VERSION ""

NS_ :

BS_:
BU_: DME_Etc
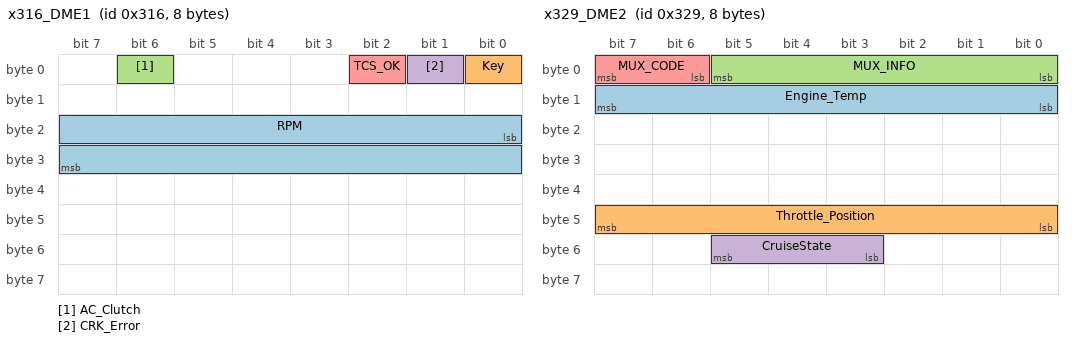
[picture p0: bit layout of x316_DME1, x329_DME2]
BO_ 790 x316_DME1: 8 DME_Etc
   SG_ RPM : 16|16@1+ (0.156,0) [0|0] "" DME_Etc
   SG_ Key : 0|1@1+ (1,0) [0|0] "" Vector__XXX
   SG_ AC_Clutch : 6|1@1+ (1,0) [0|0] "" Vector__XXX
   SG_ CRK_Error : 1|1@1+ (1,0) [0|0] "" Vector__XXX
   SG_ TCS_OK : 2|1@1+ (1,0) [0|0] "" Vector__XXX

BO_ 809 x329_DME2: 8 DME_Etc
   SG_ Engine_Temp : 8|8@1+ (0.75,-48.373) [0|0] "deg_c" Vector__XXX
   SG_ Throttle_Position : 40|8@1+ (1,0) [0|0] "%" DME_Etc
   SG_ MUX_INFO : 0|6@1+ (1,0) [0|0] "" DME_Etc
   SG_ CruiseState : 51|3@1+ (1,0) [0|0] "" DME_Etc
   SG_ MUX_CODE : 6|2@1+ (1,0) [0|0] "" DME_Etc

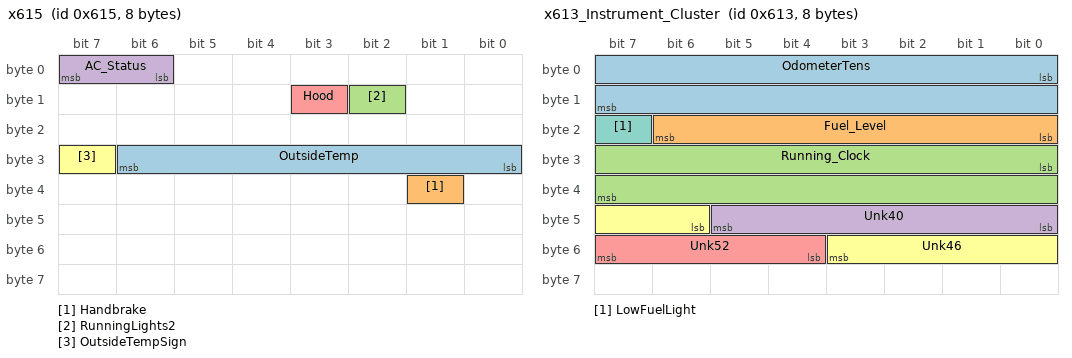
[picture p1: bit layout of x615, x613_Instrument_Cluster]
BO_ 1557 x615: 8 DME_Etc
   SG_ OutsideTemp : 24|7@1+ (1,0) [0|0] "deg_c" Vector__XXX
   SG_ Handbrake : 33|1@0+ (1,0) [0|1] "" Vector__XXX
   SG_ RunningLights2 : 10|1@0+ (1,0) [0|1] "" Vector__XXX
   SG_ AC_Status : 6|2@1+ (1,0) [0|1] "" Vector__XXX
   SG_ Hood : 11|1@0+ (1,0) [0|1] "" Vector__XXX
   SG_ OutsideTempSign : 31|1@1+ (1,0) [0|0] "" Vector__XXX

BO_ 1349 x545_DME4: 8 DME_Etc
   SG_ Fuel_Consumption : 8|16@1+ (1,0) [0|0] "mpg" DME_Etc
   SG_ Charge_Light : 40|1@1+ (1,0) [0|0] "" Vector__XXX
   SG_ Oil_Pressure_Light : 44|1@1+ (1,0) [0|0] "" DME_Etc
   SG_ OilTemp : 32|8@1+ (1,-48.373) [0|0] "deg_c" DME_Etc
   SG_ CheckEngineLight : 1|1@1+ (1,0) [0|0] "" Vector__XXX
   SG_ CruiseLight : 3|1@1+ (1,0) [0|0] "" Vector__XXX
   SG_ EML : 4|1@1+ (1,0) [0|0] "" Vector__XXX
   SG_ CheckGasCap : 6|1@1+ (1,0) [0|0] "" Vector__XXX
   SG_ OverheatLight : 27|1@1+ (1,0) [0|0] "" DME_Etc
   SG_ OilLoss : 25|1@1+ (1,0) [0|0] "" DME_Etc
   SG_ RPM7k : 28|1@1+ (1,0) [0|0] "" DME_Etc
   SG_ RPM6_5k : 29|1@1+ (1,0) [0|0] "" DME_Etc
   SG_ RPM5_5k : 30|1@1+ (1,0) [0|0] "" DME_Etc
   SG_ Unk7 : 56|8@1+ (1,0) [0|0] "" Vector__XXX
   SG_ OilConsumption : 24|1@1+ (1,0) [0|0] "" DME_Etc
   SG_ OilSensorMalfunction : 26|1@1+ (1,0) [0|0] "" DME_Etc
   SG_ UpshiftIndicator : 31|1@1+ (1,0) [0|0] "" DME_Etc

BO_ 1555 x613_Instrument_Cluster: 8 DME_Etc
   SG_ OdometerTens : 0|16@1+ (10,0) [0|0] "" Vector__XXX
   SG_ Fuel_Level : 16|7@1+ (1,0) [0|0] "" Vector__XXX
   SG_ Running_Clock : 24|16@1+ (1,0) [0|0] "minutes" DME_Etc
   SG_ Unk40 : 40|6@1+ (1,0) [0|1] "" Vector__XXX
   SG_ Unk52 : 52|4@1+ (1,0) [0|1] "" Vector__XXX
   SG_ Unk46 : 46|6@1+ (1,0) [0|1] "" Vector__XXX
   SG_ LowFuelLight : 23|1@1+ (1,0) [0|0] "" Vector__XXX

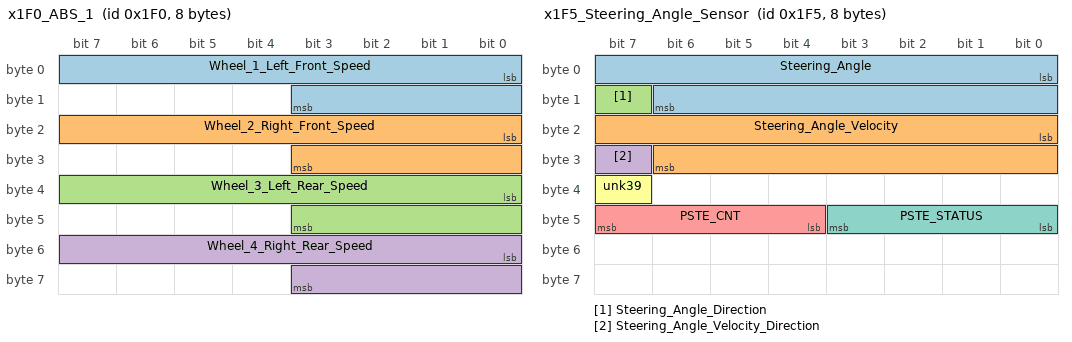
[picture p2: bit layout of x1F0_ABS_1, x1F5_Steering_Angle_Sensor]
BO_ 496 x1F0_ABS_1: 8 DME_Etc
   SG_ Wheel_1_Left_Front_Speed : 0|12@1+ (0.0625,0) [0|0] "" Vector__XXX
   SG_ Wheel_2_Right_Front_Speed : 16|12@1+ (0.0625,0) [0|0] "" DME_Etc
   SG_ Wheel_3_Left_Rear_Speed : 32|12@1+ (0.0625,0) [0|0] "" DME_Etc
   SG_ Wheel_4_Right_Rear_Speed : 48|12@1+ (0.0625,0) [0|0] "" Vector__XXX

BO_ 501 x1F5_Steering_Angle_Sensor: 8 DME_Etc
   SG_ Steering_Angle : 0|15@1+ (0.045,0) [0|0] "deg" DME_Etc
   SG_ Steering_Angle_Velocity : 16|15@1+ (0.045,0) [0|0] "deg_per_sec" DME_Etc
   SG_ Steering_Angle_Direction : 15|1@1+ (1,0) [0|0] "" Vector__XXX
   SG_ Steering_Angle_Velocity_Direction : 31|1@1+ (1,0) [0|0] "" Vector__XXX
   SG_ PSTE_CNT : 44|4@1+ (1,0) [0|0] "" Vector__XXX
   SG_ unk39 : 39|1@1+ (1,0) [0|0] "" Vector__XXX
   SG_ PSTE_STATUS : 40|4@1+ (1,0) [0|0] "" Vector__XXX

BO_ 339 ASC_1: 8 DME_Etc
   SG_ Speed : 11|13@1+ (0.0625,-0.625) [0|0] "" DME_Etc
   SG_ Brake_Pedal_Pressed : 4|1@1+ (1,0) [0|0] "" Vector__XXX
   SG_ Tyre_Pressure_Set : 0|1@1+ (1,0) [0|0] "" Vector__XXX
   SG_ Unk5 : 40|8@1+ (1,0) [0|0] "" Vector__XXX
   SG_ CheckEngineLight : 9|1@1+ (1,0) [0|0] "" Vector__XXX
   SG_ ABSLight : 7|1@1+ (1,0) [0|0] "" Vector__XXX
   SG_ unk6 : 6|1@1+ (1,0) [0|0] "" Vector__XXX
   SG_ unk2 : 2|1@1+ (1,0) [0|0] "" Vector__XXX
   SG_ unk8 : 8|1@1+ (1,0) [0|0] "" Vector__XXX
   SG_ unk60 : 60|1@1+ (1,0) [0|0] "" Vector__XXX
   SG_ unk63 : 63|1@1+ (1,0) [0|0] "" Vector__XXX
   SG_ unk32 : 32|1@1+ (1,0) [0|0] "" Vector__XXX
   SG_ unk819 : 56|7@1+ (1,0) [0|0] "" Vector__XXX

BO_ 499 x1F3: 8 DME_Etc
   SG_ ForwardForce : 24|10@1+ (1,0) [0|1024] "" Vector__XXX
   SG_ AY_REF : 38|10@1+ (1,0) [0|0] "" Vector__XXX
   SG_ unk59 : 59|1@1+ (1,0) [0|0] "" Vector__XXX
   SG_ LateralForce : 6|9@1+ (1,0) [0|1024] "" Vector__XXX
   SG_ LateralForceSign : 15|1@1+ (1,0) [0|1] "" Vector__XXX
   SG_ BAS_DEF : 16|1@1+ (1,0) [0|0] "" Vector__XXX
   SG_ Q_ACC_BAS : 17|1@1+ (1,0) [0|0] "" Vector__XXX
   SG_ BAS_FBR : 18|2@1+ (1,0) [0|0] "" Vector__XXX
   SG_ BAS_STAT : 20|4@1+ (1,0) [0|0] "" Vector__XXX
   SG_ DSC_REG : 34|1@1+ (1,0) [0|0] "" Vector__XXX
   SG_ S_HBA : 35|1@1+ (1,0) [0|0] "" Vector__XXX
   SG_ BAS_CODE : 36|2@1+ (1,0) [0|0] "" Vector__XXX
   SG_ BAS_DATEN : 48|8@1+ (1,0) [0|0] "" Vector__XXX
   SG_ FDR_MUL : 1|15@1+ (1,0) [0|0] "" Vector__XXX
   SG_ FDR_COM : 0|1@1+ (1,0) [0|0] "" Vector__XXX
   SG_ AX_REF : 24|10@1+ (1,0) [0|0] "" Vector__XXX

BO_ 1381 x565: 8 DME_Etc
   SG_ IDK2_unk1 : 55|1@1+ (1,0) [0|1] "" Vector__XXX
   SG_ IDK2_unk2 : 6|1@1+ (1,0) [0|1] "" Vector__XXX
   SG_ IDK2_unk3 : 13|1@1+ (1,0) [0|1] "" Vector__XXX
   SG_ IDK2_unk4 : 16|8@1+ (1,0) [0|1] "" Vector__XXX
   SG_ IDK2_unk5 : 25|1@1+ (1,0) [0|1] "" Vector__XXX
   SG_ IDK2_unk6 : 41|1@1+ (1,0) [0|1] "" Vector__XXX
   SG_ Unk7 : 56|8@1+ (1,0) [0|1] "" Vector__XXX
   SG_ OilPressure : 48|8@1+ (2,0) [0|0] "mPa" Vector__XXX
   SG_ Unk4 : 4|1@1+ (1,0) [0|1] "" Vector__XXX

BO_ 1560 x618: 8 DME_Etc
   SG_ Unk2 : 16|8@1+ (1,0) [0|0] "" Vector__XXX

BO_ 1567 x61F: 8 DME_Etc
   SG_ LeftTurnSignal : 22|1@0+ (1,0) [0|1] "" Vector__XXX
   SG_ AutomaticLights : 0|5@1+ (1,0) [0|1] "" Vector__XXX
   SG_ RightTurnSignal : 27|1@1+ (1,0) [0|1] "" Vector__XXX
   SG_ RunningLights : 36|1@1+ (1,0) [0|1] "" Vector__XXX
   SG_ Brights : 23|1@0+ (1,0) [0|1] "" Vector__XXX
   SG_ RunningHandbrake : 25|1@0+ (1,0) [0|1] "" Vector__XXX
   SG_ Cruise : 31|1@0+ (1,0) [0|1] "" Vector__XXX
   SG_ InteriorLightLevel : 8|6@1+ (1,0) [0|0] "" Vector__XXX
   SG_ unkStartup18 : 18|1@1+ (1,0) [0|1] "" Vector__XXX
   SG_ unkStartup30 : 30|1@1+ (1,0) [0|1] "" Vector__XXX
   SG_ unkStartup29 : 29|1@1+ (1,0) [0|1] "" Vector__XXX
   SG_ unkStartup28 : 28|1@1+ (1,0) [0|1] "" Vector__XXX
   SG_ unkStartup26 : 26|1@1+ (1,0) [0|1] "" Vector__XXX
   SG_ unkStartup24 : 24|1@1+ (1,0) [0|1] "" Vector__XXX
   SG_ unk38 : 38|1@1+ (1,0) [0|1] "" Vector__XXX
   SG_ unk19 : 19|1@1+ (1,0) [0|1] "" Vector__XXX
   SG_ unk17 : 19|1@1+ (1,0) [0|1] "" Vector__XXX
   SG_ unk16 : 19|1@1+ (1,0) [0|1] "" Vector__XXX

BO_ 1562 x61A: 8 DME_Etc
   SG_ StalkState : 56|4@1+ (1,0) [0|546654] "" Vector__XXX
   SG_ SyncClockRunning : 31|1@1+ (1,0) [0|1] "" Vector__XXX
   SG_ unk63 : 63|1@1+ (1,0) [0|1] "" Vector__XXX
   SG_ SyncClockNotRunning : 24|1@1+ (1,0) [0|1] "" Vector__XXX
   SG_ unk27 : 27|1@1+ (1,0) [0|1] "" Vector__XXX
   SG_ CustomValue : 40|16@1+ (1,0) [0|65555] "" Vector__XXX
   SG_ OdometerOnes : 0|19@1+ (1,0) [0|0] "" Vector__XXX
   SG_ OdometerTenths : 24|7@1+ (1,0) [0|0] "" Vector__XXX
   SG_ Unk4 : 32|8@1+ (1,0) [0|0] "" Vector__XXX

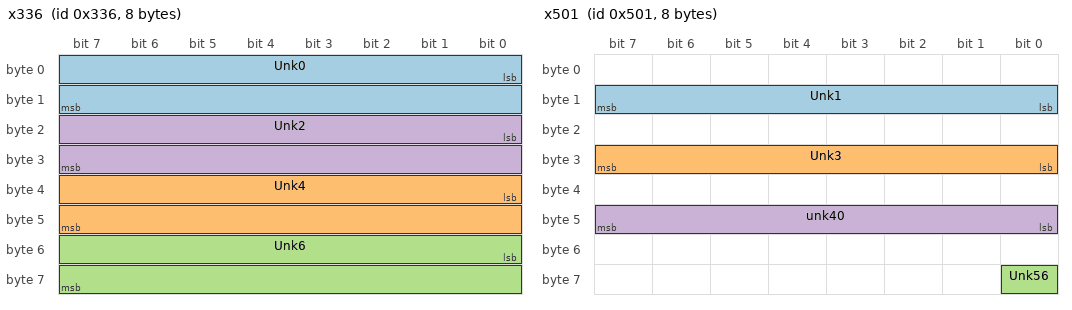
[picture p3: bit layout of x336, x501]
BO_ 822 x336: 8 DME_Etc
   SG_ Unk0 : 0|16@1+ (1,0) [0|1] "" Vector__XXX
   SG_ Unk4 : 32|16@1+ (1,0) [0|0] "" Vector__XXX
   SG_ Unk6 : 48|16@1+ (1,0) [0|0] "" Vector__XXX
   SG_ Unk2 : 16|16@1+ (1,0) [0|0] "" Vector__XXX

BO_ 504 x1F8: 8 DME_Etc
   SG_ Unk2 : 16|8@1+ (1,0) [0|1] "" Vector__XXX
   SG_ Unk0 : 0|8@1+ (1,0) [0|1] "" Vector__XXX

BO_ 1552 x610: 8 DME_Etc
   SG_ VIN : 0|64@1+ (1,0) [0|1] "" Vector__XXX

BO_ 1281 x501: 8 DME_Etc
   SG_ Unk1 : 8|8@1+ (1,0) [0|1] "" Vector__XXX
   SG_ Unk3 : 24|8@1- (1,0) [0|1] "" Vector__XXX
   SG_ Unk56 : 56|1@1+ (1,0) [0|1] "" Vector__XXX
   SG_ unk40 : 40|8@1+ (1,0) [0|0] "" Vector__XXX

BA_DEF_ BO_ "GenMsgBackgroundColor" STRING ;
BA_DEF_ BO_ "GenMsgForegroundColor" STRING ;
BA_DEF_DEF_ "GenMsgBackgroundColor" "#ffffff";
BA_DEF_DEF_ "GenMsgForegroundColor" "#000000";
CM_ SG_ 790 CRK_Error "Crankshaft_sensor_state";
CM_ SG_ 1349 Unk7 "Temp_in_F_maybe";
CM_ SG_ 1555 Unk40 "Driver_side_fuel_maybe?";
CM_ SG_ 501 PSTE_CNT "Telegram_Counter";
CM_ SG_ 501 PSTE_STATUS "Internal_Status_Code";
CM_ SG_ 339 Tyre_Pressure_Set "LV_ASC_REQ";
CM_ SG_ 339 ABSLight "LV_ABS_LED";
CM_ SG_ 339 unk6 "LV_EBV";
CM_ SG_ 339 unk2 "LV_ASC_PASV";
CM_ SG_ 499 ForwardForce "AX_REF";
CM_ SG_ 499 LateralForce "FDR_MUL";
CM_ BO_ 822 "Values seem to be engine-related";
VAL_ 790 Key 0 "Off" 1 "On";
VAL_ 790 AC_Clutch 0 "Off" 1 "On";
VAL_ 809 CruiseState 0 "Inactive" 1 "Constant_Drive" 2 "Resume" 5 "Set/Acceleration" 7 "Deceleration";
VAL_ 809 MUX_CODE 0 "CAN_LEVEL" 2 "OBD_STEUR" 3 "MD_NORM";
VAL_ 1349 Charge_Light 0 "Off" 1 "On";
VAL_ 1349 Oil_Pressure_Light 0 "Off" 1 "On";
VAL_ 339 Brake_Pedal_Pressed 0 "Not_pressed" 1 "Pressed";
